# APM32F425 register map
File version: 1.0
CPU: CM4 r1p0, little endian, no MPU, no FPU, 4 interrupt priority bits
Registers are 32-bit, read-write, reset 0x0 unless marked. A register's access mark holds for its fields unless they carry their own. Offsets are from the block's base; [hi:lo] are bit positions.

## IWDT — Independent watchdog
Base 0x40003000
0x00 KEY wo
  [15:0] KEY — Key value (write only, read 0000h)
0x04 PSC — Prescaler register
  [2:0] PSC — Prescaler divider
0x08 CNTRLD reset 0xFFF — Reload register
  [11:0] CNTRLD — Watchdog counter reload value
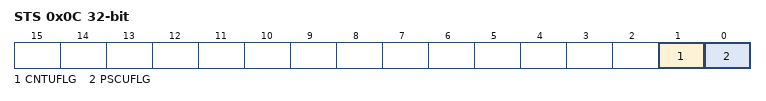
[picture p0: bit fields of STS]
0x0C STS ro — Status register
  [1] CNTUFLG — Watchdog counter reload value update
  [0] PSCUFLG — Watchdog prescaler value update

## WWDT — Window watchdog
Base 0x40002C00
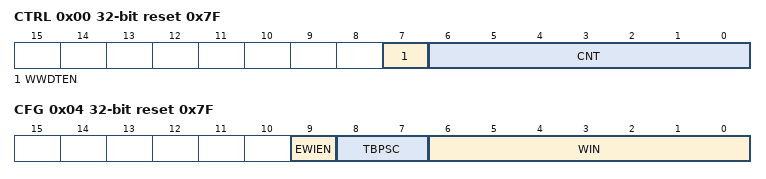
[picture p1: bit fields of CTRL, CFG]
0x00 CTRL reset 0x7F — Control register
  [7] WWDTEN — Activation bit
  [6:0] CNT — 7-bit counter (MSB to LSB)
0x04 CFG reset 0x7F — Configuration register
  [9] EWIEN — Early wakeup interrupt
  [8:7] TBPSC — Timer Base Prescaler Factor Configure
  [6:0] WIN — 7-bit window value
0x08 STS — Status register
  [0] EWIFLG — Early wakeup interrupt flag

## UART4 — Universal synchronous asynchronous receiver transmitter
Base 0x40004C00
Same registers: UART5 0x40005000
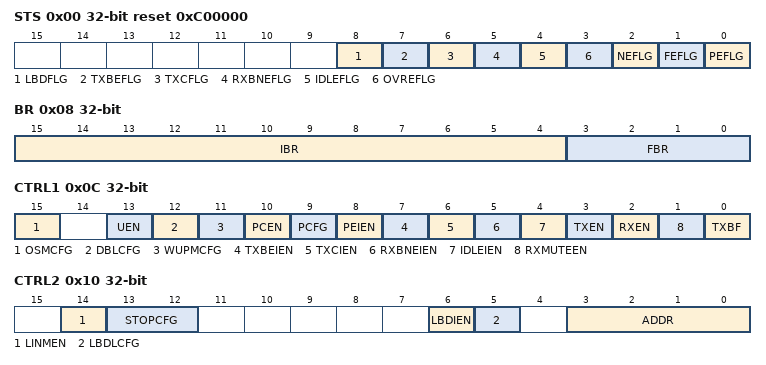
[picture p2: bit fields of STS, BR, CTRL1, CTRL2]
0x00 STS access per field reset 0xC00000 — Status register
  [8] LBDFLG rw — LIN break detection flag
  [7] TXBEFLG ro — Transmit data register empty
  [6] TXCFLG rw — Transmission complete
  [5] RXBNEFLG rw — Read data register not empty
  [4] IDLEFLG ro — IDLE line detected
  [3] OVREFLG ro — Overrun error
  [2] NEFLG ro — Noise detected flag
  [1] FEFLG ro — Framing error
  [0] PEFLG ro — Parity error
0x04 DATA
  [8:0] DATA — Data value
0x08 BR — Baud rate register
  [15:4] IBR — mantissa of USARTDIV
  [3:0] FBR — fraction of USARTDIV
0x0C CTRL1 — Control register 1
  [15] OSMCFG — Oversampling mode
  [13] UEN — USART enable
  [12] DBLCFG — Word length
  [11] WUPMCFG — Wakeup method
  [10] PCEN — Parity control enable
  [9] PCFG — Parity selection
  [8] PEIEN — PE interrupt enable
  [7] TXBEIEN — TXE interrupt enable
  [6] TXCIEN — Transmission complete interrupt enable
  [5] RXBNEIEN — RXNE interrupt enable
  [4] IDLEIEN — IDLE interrupt enable
  [3] TXEN — Transmitter enable
  [2] RXEN — Receiver enable
  [1] RXMUTEEN — Receiver wakeup
  [0] TXBF — Send break
0x10 CTRL2 — Control register 2
  [14] LINMEN — LIN mode enable
  [13:12] STOPCFG — STOP bits
  [6] LBDIEN — LIN break detection interrupt enable
  [5] LBDLCFG — lin break detection length
  [3:0] ADDR — Address of the USART node
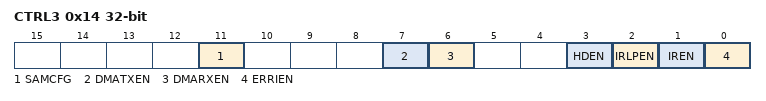
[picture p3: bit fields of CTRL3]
0x14 CTRL3 — Control register 3
  [11] SAMCFG — One sample bit method enable
  [7] DMATXEN — DMA enable transmitter
  [6] DMARXEN — DMA enable receiver
  [3] HDEN — Half-duplex selection
  [2] IRLPEN — IrDA low-power
  [1] IREN — IrDA mode enable
  [0] ERRIEN — Error interrupt enable

## ADC_CCTRL — ADC Common control registers
Base 0x40012300
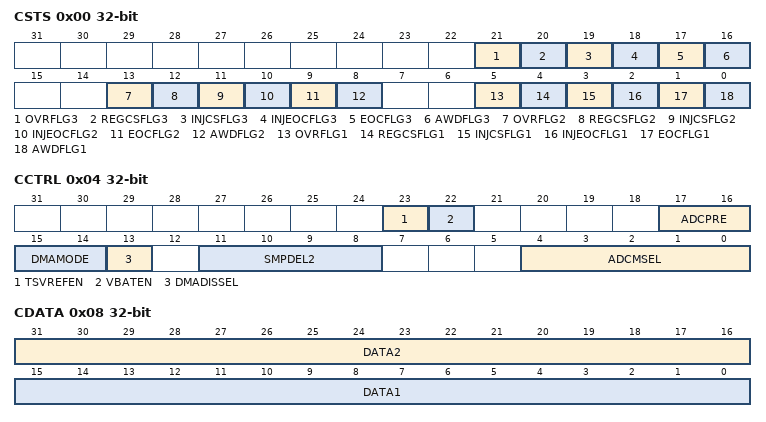
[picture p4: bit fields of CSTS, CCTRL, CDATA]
0x00 CSTS ro — ADC Common status register
  [21] OVRFLG3 — Overrun flag of ADC3
  [20] REGCSFLG3 — Regular channel Start flag of ADC 3
  [19] INJCSFLG3 — Injected channel Start flag of ADC 3
  [18] INJEOCFLG3 — Injected channel end of conversion of ADC 3
  [17] EOCFLG3 — End of conversion of ADC 3
  [16] AWDFLG3 — Analog watchdog flag of ADC 3
  [13] OVRFLG2 — Overrun flag of ADC 2
  [12] REGCSFLG2 — Regular channel Start flag of ADC 2
  [11] INJCSFLG2 — Injected channel Start flag of ADC 2
  [10] INJEOCFLG2 — Injected channel end of conversion of ADC 2
  [9] EOCFLG2 — End of conversion of ADC 2
  [8] AWDFLG2 — Analog watchdog flag of ADC 2
  [5] OVRFLG1 — Overrun flag of ADC 1
  [4] REGCSFLG1 — Regular channel Start flag of ADC 1
  [3] INJCSFLG1 — Injected channel Start flag of ADC 1
  [2] INJEOCFLG1 — Injected channel end of conversion of ADC 1
  [1] EOCFLG1 — End of conversion of ADC 1
  [0] AWDFLG1 — Analog watchdog flag of ADC 1
0x04 CCTRL — ADC common control register
  [23] TSVREFEN — Temperature sensor and VREFINT enable
  [22] VBATEN — VBAT enable
  [17:16] ADCPRE — ADC prescaler
  [15:14] DMAMODE — Direct memory access mode for multi ADC mode
  [13] DMADISSEL — DMA disable selection for multi-ADC mode
  [11:8] SMPDEL2 — Delay between 2 sampling phases
  [4:0] ADCMSEL — Multi ADC mode selection
0x08 CDATA ro — ADC common regular data register for dual and triple modes
  [31:16] DATA2 — 2nd data item of a pair of regular conversions
  [15:0] DATA1 — 1st data item of a pair of regular conversions
